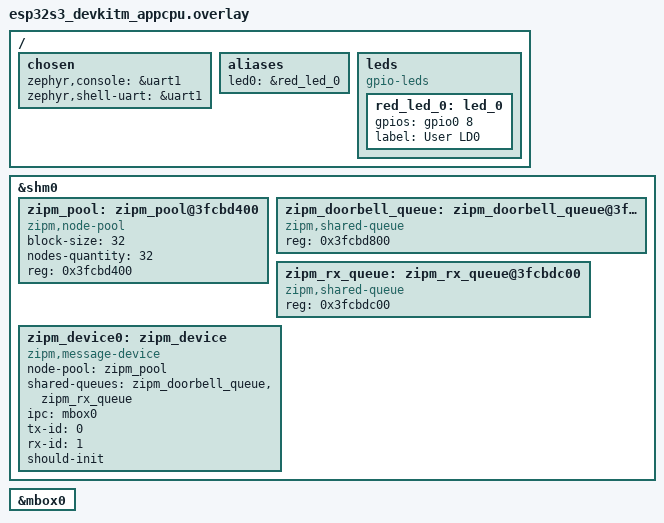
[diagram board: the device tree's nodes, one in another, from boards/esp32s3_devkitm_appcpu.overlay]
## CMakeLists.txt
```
# SPDX-License-Identifier: Apache-2.0

cmake_minimum_required(VERSION 3.20.0)

find_package(Zephyr REQUIRED HINTS $ENV{ZEPHYR_BASE})
project(zipm_rx)

target_sources(app PRIVATE src/main.c)
```

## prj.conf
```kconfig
CONFIG_ZIPM=y
CONFIG_IPM=y
CONFIG_SYSTEM_WORKQUEUE_STACK_SIZE=4096
```

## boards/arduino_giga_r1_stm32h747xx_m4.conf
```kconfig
CONFIG_SHELL=y
CONFIG_PRINTK=y
CONFIG_LOG=y

CONFIG_SERIAL=y
CONFIG_CONSOLE=y
CONFIG_UART_CONSOLE=y
CONFIG_UART_LINE_CTRL=y
CONFIG_MBOX_STM32_HSEM=y
```

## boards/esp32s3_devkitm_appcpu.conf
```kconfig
CONFIG_IPM=y
CONFIG_MAIN_STACK_SIZE=2048

CONFIG_CONSOLE=y
CONFIG_SERIAL=y
CONFIG_UART_CONSOLE=y
CONFIG_GPIO=y
CONFIG_CLOCK_CONTROL=y
```

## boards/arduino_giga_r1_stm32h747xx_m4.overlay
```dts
/*
 * Copyright (c) 2024 Felipe Neves
 *
 * SPDX-License-Identifier: Apache-2.0
 */

 / {
	chosen {
		/delete-property/ zephyr,ipc_shm;
	};

	/* We redefine the memory and remove the cache attr due to cache coherence issues */
	/delete-node/ memory@38000000;

	shared_ram: memory@38000000 {
		 zephyr,memory-region = "shared_ram";
		 compatible = "zephyr,memory-region", "mmio-sram";
		 reg = <0x38000000 0x10000>;
		 zephyr,memory-attr = <( DT_MEM_ARM(ATTR_MPU_RAM_NOCACHE) )>;
	 };
};

&shared_ram {
	#address-cells = <1>;
	#size-cells = <0>;
  
	zipm_pool: zipm_pool@38000000 {
		compatible = "zipm,node-pool";
		block-size = <32>;
		nodes-quantity = <32>;
		reg = <0x38000000>;
	};

	zipm_doorbell_queue: zipm_doorbell_queue@38008000 {
		compatible = "zipm,shared-queue";
		reg = <0x38008000>;
	};
  
	zipm_tx_queue: zipm_tx_queue@38008400 {
		compatible = "zipm,shared-queue";
		reg = <0x38008400>;
	};

	zipm_device0: zipm_device {
        compatible = "zipm,message-device";
        status = "okay";
        node-pool = <&zipm_pool>;
        shared-queues = <&zipm_doorbell_queue &zipm_tx_queue>;
        ipc = <&mailbox>;
		tx-id = <10>;
		rx-id = <11>;
    };
};

&mailbox {
	status = "okay";
};
```

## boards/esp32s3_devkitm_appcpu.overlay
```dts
/*
 * Copyright (c) 2024 Felipe Neves
 *
 * SPDX-License-Identifier: Apache-2.0
 */
/ {
	chosen {
		zephyr,console = &uart1;
		zephyr,shell-uart = &uart1;
	};

	aliases {
		led0 = &red_led_0;
	};

	leds {
		compatible = "gpio-leds";
		red_led_0: led_0 {
			gpios = <&gpio0 8 GPIO_ACTIVE_HIGH>;
			label = "User LD0";
		};
	};
};

&shm0 {
	#address-cells = <1>;
	#size-cells = <0>;

	zipm_pool: zipm_pool@3fcbd400 {
		compatible = "zipm,node-pool";
		block-size = <32>;
		nodes-quantity = <32>;
		reg = <0x3fcbd400>;
	};

	zipm_doorbell_queue: zipm_doorbell_queue@3fcbd800 {
		compatible = "zipm,shared-queue";
		reg = <0x3fcbd800>;
	};

	zipm_rx_queue: zipm_rx_queue@3fcbdc00 {
		compatible = "zipm,shared-queue";
		reg = <0x3fcbdc00>;
	};

	zipm_device0: zipm_device {
        compatible = "zipm,message-device";
        status = "okay";
        node-pool = <&zipm_pool>;
        shared-queues = <&zipm_doorbell_queue &zipm_rx_queue>;
        ipc = <&mbox0>;
		tx-id = <0>;
		rx-id = <1>;
		should-init;
    };
};

&mbox0 {
	status = "okay";
};
```

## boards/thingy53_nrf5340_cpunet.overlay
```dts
/*
 * Copyright (c) 2024 Felipe Neves
 *
 * SPDX-License-Identifier: Apache-2.0
 */

&sram0_shared {
	#address-cells = <1>;
	#size-cells = <0>;
  
	zipm_pool: zipm_pool@20078000 {
		compatible = "zipm,node-pool";
		block-size = <32>;
		nodes-quantity = <32>;
		reg = <0x20078000>;
	};

	zipm_doorbell_queue: zipm_doorbell_queue@2007C000 {
		compatible = "zipm,shared-queue";
		reg = <0x2007C000>;
	};
  
	zipm_rx_queue: zipm_rx_queue@2007C400 {
		compatible = "zipm,shared-queue";
		reg = <0x2007C400>;
	};

	zipm_device0: zipm_device {
        compatible = "zipm,message-device";
        status = "okay";
        node-pool = <&zipm_pool>;
        shared-queues = <&zipm_doorbell_queue &zipm_rx_queue>;
        ipc = <&mbox>;
		tx-id = <1>;
		rx-id = <0>;
    };
};
```

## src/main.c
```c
/*
 * Copyright (c) 2024 Felipe Neves
 *
 * SPDX-License-Identifier: Apache-2.0
 */

#include <stdio.h>
#include <zephyr/kernel.h>
#include <zephyr/drivers/gpio.h>
#include <zephyr/drivers/uart.h>
#include <zephyr/usb/usb_device.h>
#include <zipm/zipm.h>

static const struct gpio_dt_spec led = GPIO_DT_SPEC_GET(DT_ALIAS(led0), gpios);
static const struct device *handle = DEVICE_DT_GET(DT_NODELABEL(zipm_device0));
static struct zipm_callback callback;
static const char msg[] = {"Hello from other side! Aka secondary core! \0"};
static char rx_msg[64] = {0};
const int doorbell_queue = 0;
const int tx_queue = 1;

static void zipm_event_callback(const struct device *dev, int sq, void *user_data)
{
	if(sq == doorbell_queue) {
		gpio_pin_toggle_dt(&led);
		zipm_receive(dev, &rx_msg, NULL, doorbell_queue);
		zipm_send(dev, &msg, sizeof(msg), tx_queue, 0);

		printk("Primary core asked: %s, so let's say something \n", (const char *)rx_msg);
	}
}

int main(void)
{
	zipm_register_event_callback(handle, &callback, zipm_event_callback, NULL);
	if (!gpio_is_ready_dt(&led)) {
		return 0;
	}

	gpio_pin_configure_dt(&led, GPIO_OUTPUT_ACTIVE);
	return 0;
}
```
